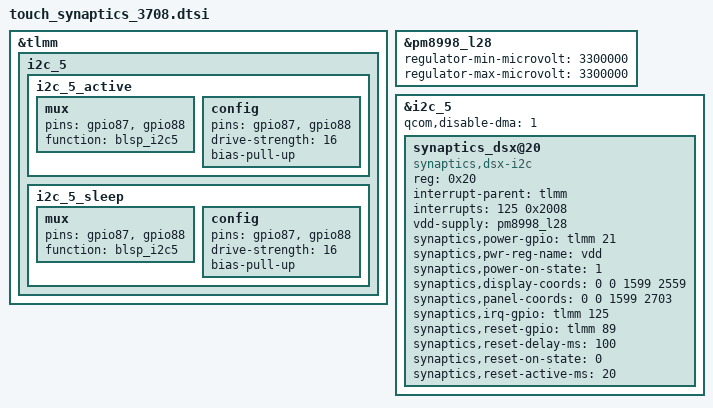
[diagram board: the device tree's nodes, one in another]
&tlmm {
	i2c_5 {
		i2c_5_active: i2c_5_active {
			mux {
				pins = "gpio87", "gpio88";
				function = "blsp_i2c5";
			};
			config {
				pins = "gpio87", "gpio88";
				drive-strength = <16>;
				bias-pull-up;
			};
		};

		i2c_5_sleep: i2c_5_sleep {
			mux {
				pins = "gpio87", "gpio88";
				function = "blsp_i2c5";
			};
			config {
				pins = "gpio87", "gpio88";
				drive-strength = <16>;
				bias-pull-up;
			};
		};
	};
};

&pm8998_l28{
    regulator-min-microvolt = <3300000>;
    regulator-max-microvolt = <3300000>;
    status = "okay";
};

&i2c_5{
	qcom,disable-dma = <1>;
	status = "okay";
	/delete-node/ synaptics@20;
	synaptics_dsx@20 {
		compatible = "synaptics,dsx-i2c";
		reg = <0x20>;
		interrupt-parent = <&tlmm>;
		interrupts = <125 0x2008>;
		vdd-supply = <&pm8998_l28>;
		//pinctrl-names = "pmx_ts_active", "pmx_ts_suspend";
		//pinctrl-0 = <&msm8998_gpio89_active &msm8998_gpio125_active >;
		//pinctrl-1 = <&msm8998_gpio89_suspend &msm8998_gpio125_suspend >;
		synaptics,power-gpio = <&tlmm 21 0x00>;
		synaptics,pwr-reg-name = "vdd";
		synaptics,power-on-state = <1>;
		synaptics,display-coords = <0 0 1599 2559>;
		synaptics,panel-coords = <0 0 1599 2703>;
		synaptics,irq-gpio = <&tlmm 125 0x2008>;  /* IRQF_ONESHOT | IRQF_TRIGGER_LOW */
		synaptics,reset-gpio = <&tlmm 89 0x00>;
		synaptics,reset-delay-ms = <100>;
		synaptics,reset-on-state = <0>;
		synaptics,reset-active-ms = <20>;
	};
};
